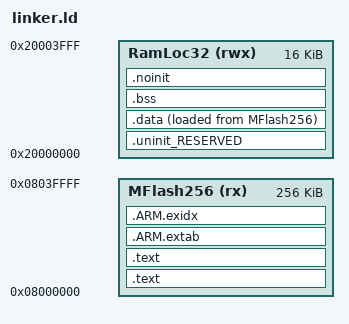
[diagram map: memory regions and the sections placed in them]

MEMORY
{
  /* Define each memory region */
  MFlash256 (rx) : ORIGIN = 0x08000000, LENGTH = 0x40000 /* 256K bytes (alias Flash) */  
  RamLoc32 (rwx) : ORIGIN = 0x20000000, LENGTH = 0x4000 /* 16kb bytes (alias RAM) */ 
}

  /* Define a symbol for the top of each memory region */
  __base_MFlash256 = 0x08000000  ; /* MFlash256 */  
  __base_Flash = 0x08000000 ; /* Flash */  
  __top_MFlash256 = 0x08000000 + 0x40000 ; /* 256K bytes */  
  __top_Flash = 0x08000000 + 0x40000 ; /* 256K bytes */  
  __base_RamLoc32 = 0x20000000  ; /* RamLoc32 */  
  __base_RAM = 0x20000000 ; /* RAM */  
  __top_RamLoc32 = 0x20000000 + 0x4000 ; /* 16kb bytes */  
  __top_RAM = 0x20000000 + 0x4000 ; /* 16K bytes */    


ENTRY(main)

SECTIONS
{
     /* MAIN TEXT SECTION */
    .text : ALIGN(4)
    {
        FILL(0xff)
        __vectors_start__ = ABSOLUTE(.) ;
        KEEP(*(.isr_vector))
        /* Global Section Table */
        . = ALIGN(4) ;
        __section_table_start = .;
        __data_section_table = .;
        LONG(LOADADDR(.data));
        LONG(    ADDR(.data));
        LONG(  SIZEOF(.data));
        __data_section_table_end = .;
        __bss_section_table = .;
        LONG(    ADDR(.bss));
        LONG(  SIZEOF(.bss));
        __bss_section_table_end = .;
        __section_table_end = . ;
        /* End of Global Section Table */

        KEEP(*(.after_vectors*))

    } > MFlash256

    .text : ALIGN(4)
    {
       *(.text*)
       *(.rodata .rodata.* .constdata .constdata.*)
       . = ALIGN(4);
    } > MFlash256
    /*
     * for exception handling/unwind - some Newlib functions (in common
     * with C++ and STDC++) use this.
     */
    .ARM.extab : ALIGN(4)
    {
        *(.ARM.extab* .gnu.linkonce.armextab.*)
    } > MFlash256

    .ARM.exidx : ALIGN(4)
    {
        __exidx_start = .;
        *(.ARM.exidx* .gnu.linkonce.armexidx.*)
        __exidx_end = .;
    } > MFlash256
 
    _etext = .;

    /* MAIN DATA SECTION */
    .uninit_RESERVED (NOLOAD) : ALIGN(4)
    {
        _start_uninit_RESERVED = .;
        KEEP(*(.bss.$RESERVED*))
       . = ALIGN(4) ;
        _end_uninit_RESERVED = .;
    } > RamLoc32 AT> RamLoc32

    /* Main DATA section (RamLoc32) */
    .data : ALIGN(4)
    {
       FILL(0xff)
       _data = . ;
       PROVIDE(__start_data_RAM = .) ;
       PROVIDE(__start_data_RamLoc32 = .) ;
       *(vtable)
       *(.ramfunc*)
       KEEP(*(CodeQuickAccess))
       KEEP(*(DataQuickAccess))
       *(RamFunction)
       *(.data*)
       . = ALIGN(4) ;
       _edata = . ;
       PROVIDE(__end_data_RAM = .) ;
       PROVIDE(__end_data_RamLoc32 = .) ;
    } > RamLoc32 AT>MFlash256

    /* MAIN BSS SECTION */
    .bss : ALIGN(4)
    {
        _bss = .;
        PROVIDE(__start_bss_RAM = .) ;
        PROVIDE(__start_bss_RamLoc32 = .) ;
        *(.bss*)
        *(COMMON)
        . = ALIGN(4) ;
        _ebss = .;
        PROVIDE(__end_bss_RAM = .) ;
        PROVIDE(__end_bss_RamLoc32 = .) ;
        PROVIDE(end = .);
    } > RamLoc32 AT> RamLoc32

    /* DEFAULT NOINIT SECTION */
    .noinit (NOLOAD): ALIGN(4)
    {
        _noinit = .;
        PROVIDE(__start_noinit_RAM = .) ;
        PROVIDE(__start_noinit_RamLoc32 = .) ;
        *(.noinit*)
         . = ALIGN(4) ;
        _end_noinit = .;
       PROVIDE(__end_noinit_RAM = .) ;
       PROVIDE(__end_noinit_RamLoc32 = .) ;        
    } > RamLoc32 AT> RamLoc32
    PROVIDE(_pvHeapStart = DEFINED(__user_heap_base) ? __user_heap_base : .);
    PROVIDE(_vStackTop = DEFINED(__user_stack_top) ? __user_stack_top : __top_RamLoc32 - 0);

    /* ## Create checksum value (used in startup) ## */
    PROVIDE(__valid_user_code_checksum = 0 - 
                                         (_vStackTop 
                                         + (main + 1) 
                                         + (NMI_Handler + 1) 
                                         + (HardFault_Handler + 1) 
                                         + (( DEFINED(MemManage_Handler) ? MemManage_Handler : 0 ) + 1)   /* MemManage_Handler may not be defined */
                                         + (( DEFINED(BusFault_Handler) ? BusFault_Handler : 0 ) + 1)     /* BusFault_Handler may not be defined */
                                         + (( DEFINED(UsageFault_Handler) ? UsageFault_Handler : 0 ) + 1) /* UsageFault_Handler may not be defined */
                                         ) );

    /* Provide basic symbols giving location and size of main text
     * block, including initial values of RW data sections. Note that
     * these will need extending to give a complete picture with
     * complex images (e.g multiple Flash banks).
     */
    _image_start = LOADADDR(.text);
    _image_end = LOADADDR(.data) + SIZEOF(.data);
    _image_size = _image_end - _image_start;
}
